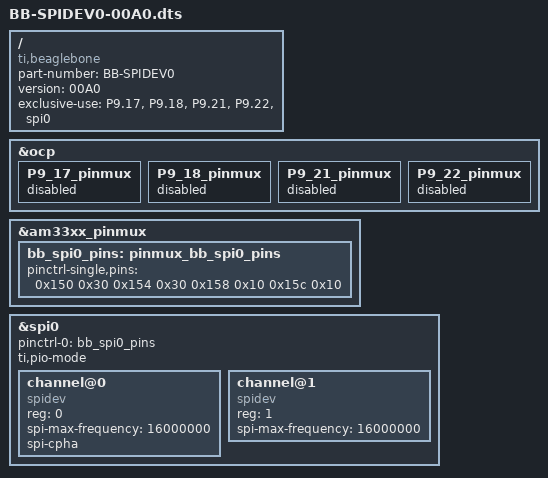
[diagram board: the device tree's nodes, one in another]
/*
 * Copyright (C) 2013 CircuitCo
 *
 * Virtual cape for SPI0 on connector pins P9.22 P9.21 P9.18 P9.17
 *
 * This program is free software; you can redistribute it and/or modify
 * it under the terms of the GNU General Public License version 2 as
 * published by the Free Software Foundation.
 */

/dts-v1/;
/plugin/;

#include <dt-bindings/board/am335x-bbw-bbb-base.h>
#include <dt-bindings/pinctrl/am33xx.h>

/ {
	compatible = "ti,beaglebone", "ti,beaglebone-black", "ti,beaglebone-green";

	/* identification */
	part-number = "BB-SPIDEV0";
	version = "00A0";

	/* state the resources this cape uses */
	exclusive-use =
		/* the pin header uses */
		"P9.17",	/* spi0_cs0 */
		"P9.18",	/* spi0_d1 */
		"P9.21",	/* spi0_d0 */
		"P9.22",	/* spi0_sclk */
		/* the hardware ip uses */
		"spi0";

	/*
	 * Free up the pins used by the cape from the pinmux helpers.
	 */
	fragment@0 {
		target = <&ocp>;
		__overlay__ {
			P9_17_pinmux { status = "disabled"; };	/* spi0_cs0 */
			P9_18_pinmux { status = "disabled"; };	/* spi0_d1 */
			P9_21_pinmux { status = "disabled"; };	/* spi0_d0 */
			P9_22_pinmux { status = "disabled"; };	/* spi0_sclk */
		};
	};

	fragment@1 {
		target = <&am33xx_pinmux>;
		__overlay__ {
			bb_spi0_pins: pinmux_bb_spi0_pins {
				pinctrl-single,pins = <
					0x150 0x30	/* spi0_sclk.spi0_sclk, INPUT_PULLUP | MODE0 */
					0x154 0x30	/* spi0_d0.spi0_d0, INPUT_PULLUP | MODE0 */
					0x158 0x10	/* spi0_d1.spi0_d1, OUTPUT_PULLUP | MODE0 */
					0x15c 0x10	/* spi0_cs0.spi0_cs0, OUTPUT_PULLUP | MODE0 */
				>;
			};
		};
	};

	fragment@2 {
		target = <&spi0>;
		__overlay__ {
			#address-cells = <1>;
			#size-cells = <0>;

			status = "okay";
			pinctrl-names = "default";
			pinctrl-0 = <&bb_spi0_pins>;
			ti,pio-mode; /* disable dma when used as an overlay, dma gets stuck at 160 bits... */

			channel@0 {
				#address-cells = <1>;
				#size-cells = <0>;

				compatible = "spidev";

				reg = <0>;
				spi-max-frequency = <16000000>;
				spi-cpha;
			};

			channel@1 {
				#address-cells = <1>;
				#size-cells = <0>;

				compatible = "spidev";

				reg = <1>;
				spi-max-frequency = <16000000>;
			};
		};
	};
};
